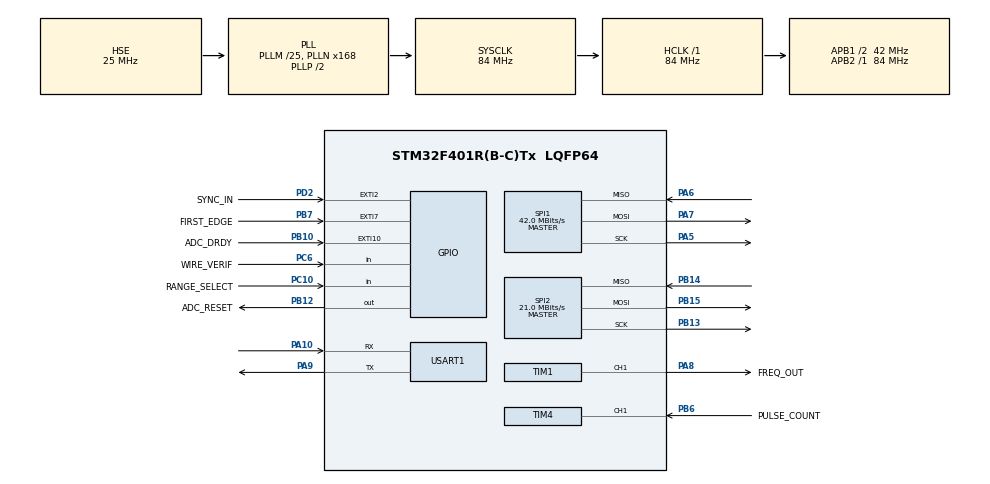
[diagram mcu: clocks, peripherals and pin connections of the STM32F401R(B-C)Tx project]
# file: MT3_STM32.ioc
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Mcu.Family=STM32F4
Mcu.Name=STM32F401R(B-C)Tx
Mcu.Package=LQFP64
NVIC.PriorityGroup=NVIC_PRIORITYGROUP_4
PA10.Mode=Asynchronous
PA10.Signal=USART1_RX
PA13.Mode=Serial_Wire
PA13.Signal=SYS_JTMS-SWDIO
PA14.Mode=Serial_Wire
PA14.Signal=SYS_JTCK-SWCLK
PA5.Mode=Full_Duplex_Master
PA5.Signal=SPI1_SCK
PA6.Mode=Full_Duplex_Master
PA6.Signal=SPI1_MISO
PA7.Mode=Full_Duplex_Master
PA7.Signal=SPI1_MOSI
PA8.GPIO_Label=FREQ_OUT
PA8.Signal=S_TIM1_CH1
PA9.Mode=Asynchronous
PA9.Signal=USART1_TX
PB10.GPIO_Label=ADC_DRDY
PB10.Signal=GPXTI10
PB12.GPIO_Label=ADC_RESET
PB12.Signal=GPIO_Output
PB13.Mode=Full_Duplex_Master
PB13.Signal=SPI2_SCK
PB14.Mode=Full_Duplex_Master
PB14.Signal=SPI2_MISO
PB15.Mode=Full_Duplex_Master
PB15.Signal=SPI2_MOSI
PB6.GPIO_Label=PULSE_COUNT
PB6.Signal=S_TIM4_CH1
PB7.GPIO_Label=FIRST_EDGE
PB7.Signal=GPXTI7
PC10.GPIO_Label=RANGE_SELECT
PC10.Signal=GPIO_Input
PC6.GPIO_Label=WIRE_VERIF
PC6.Signal=GPIO_Input
PD2.GPIO_Label=SYNC_IN
PD2.Signal=GPXTI2
PH0\ -\ OSC_IN.Mode=HSE-External-Oscillator
PH0\ -\ OSC_IN.Signal=RCC_OSC_IN
PH1\ -\ OSC_OUT.Mode=HSE-External-Oscillator
PH1\ -\ OSC_OUT.Signal=RCC_OSC_OUT
ProjectManager.HeapSize=0x200
ProjectManager.StackSize=0x400
ProjectManager.TargetToolchain=CMake
RCC.48MHZClocksFreq_Value=42000000
RCC.AHBFreq_Value=84000000
RCC.APB1CLKDivider=RCC_HCLK_DIV2
RCC.APB1Freq_Value=42000000
RCC.APB1TimFreq_Value=84000000
RCC.APB2Freq_Value=84000000
RCC.APB2TimFreq_Value=84000000
RCC.CortexFreq_Value=84000000
RCC.HCLKFreq_Value=84000000
RCC.HSE_VALUE=25000000
RCC.HSI_VALUE=16000000
RCC.LSE_VALUE=32768
RCC.PLLM=25
RCC.PLLN=168
RCC.PLLSourceVirtual=RCC_PLLSOURCE_HSE
RCC.SYSCLKFreq_VALUE=84000000
RCC.SYSCLKSource=RCC_SYSCLKSOURCE_PLLCLK
RCC.VCOOutputFreq_Value=168000000
SH.S_TIM1_CH1.0=TIM1_CH1,PWM Generation1 CH1
SH.S_TIM4_CH1.0=TIM4_CH1,Input_Capture1_from_TI1
SPI1.BaudRatePrescaler=SPI_BAUDRATEPRESCALER_2
SPI1.CalculateBaudRate=42.0 MBits/s
SPI1.Direction=SPI_DIRECTION_2LINES
SPI1.Mode=SPI_MODE_MASTER
SPI1.VirtualType=VM_MASTER
SPI2.BaudRatePrescaler=SPI_BAUDRATEPRESCALER_2
SPI2.CalculateBaudRate=21.0 MBits/s
SPI2.Direction=SPI_DIRECTION_2LINES
SPI2.Mode=SPI_MODE_MASTER
SPI2.VirtualType=VM_MASTER
TIM1.Channel-PWM\ Generation1\ CH1=TIM_CHANNEL_1
TIM4.Channel-Input_Capture1_from_TI1=TIM_CHANNEL_1
USART1.VirtualMode=VM_ASYNC
board=custom

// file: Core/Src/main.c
/* USER CODE BEGIN Header */
/**
  ******************************************************************************
  * @file           : main.c
  * @brief          : Main program body
  ******************************************************************************
  * @attention
  *
  * Copyright (c) 2026 STMicroelectronics.
  * All rights reserved.
  *
  * This software is licensed under terms that can be found in the LICENSE file
  * in the root directory of this software component.
  * If no LICENSE file comes with this software, it is provided AS-IS.
  *
  ******************************************************************************
  */
/* USER CODE END Header */
#include "main.h"
#include "spi.h"
#include "tim.h"
#include "usart.h"
#include "gpio.h"

/* USER CODE BEGIN Includes */
#include "mvp_telemetry.h"

/* USER CODE END Includes */

void SystemClock_Config(void);

int main(void)
{

  /* MCU Configuration--------------------------------------------------------*/

  /* Reset of all peripherals, Initializes the Flash interface and the Systick. */
  HAL_Init();

  /* Configure the system clock */
  SystemClock_Config();

  /* Initialize all configured peripherals */
  MX_GPIO_Init();
  MX_SPI1_Init();
  MX_SPI2_Init();
  MX_TIM1_Init();
  MX_TIM4_Init();
  MX_USART1_UART_Init();
  /* USER CODE BEGIN 2 */
  MvpTelemetry_Init();

  /* USER CODE END 2 */

  /* Infinite loop */
  while (1)
  {

    /* USER CODE BEGIN 3 */
    MvpTelemetry_Poll();
    __WFI();
  }
  /* USER CODE END 3 */
}

void SystemClock_Config(void)
{
  RCC_OscInitTypeDef RCC_OscInitStruct = {0};
  RCC_ClkInitTypeDef RCC_ClkInitStruct = {0};

  /** Configure the main internal regulator output voltage
  */
  __HAL_RCC_PWR_CLK_ENABLE();
  __HAL_PWR_VOLTAGESCALING_CONFIG(PWR_REGULATOR_VOLTAGE_SCALE2);

  /** Initializes the RCC Oscillators according to the specified parameters
  * in the RCC_OscInitTypeDef structure.
  */
  RCC_OscInitStruct.OscillatorType = RCC_OSCILLATORTYPE_HSE;
  RCC_OscInitStruct.HSEState = RCC_HSE_ON;
  RCC_OscInitStruct.PLL.PLLState = RCC_PLL_ON;
  RCC_OscInitStruct.PLL.PLLSource = RCC_PLLSOURCE_HSE;
  RCC_OscInitStruct.PLL.PLLM = 25;
  RCC_OscInitStruct.PLL.PLLN = 168;
  RCC_OscInitStruct.PLL.PLLP = RCC_PLLP_DIV2;
  RCC_OscInitStruct.PLL.PLLQ = 4;
  if (HAL_RCC_OscConfig(&RCC_OscInitStruct) != HAL_OK)
  {
    Error_Handler();
  }

  /** Initializes the CPU, AHB and APB buses clocks
  */
  RCC_ClkInitStruct.ClockType = RCC_CLOCKTYPE_HCLK|RCC_CLOCKTYPE_SYSCLK
                              |RCC_CLOCKTYPE_PCLK1|RCC_CLOCKTYPE_PCLK2;
  RCC_ClkInitStruct.SYSCLKSource = RCC_SYSCLKSOURCE_PLLCLK;
  RCC_ClkInitStruct.AHBCLKDivider = RCC_SYSCLK_DIV1;
  RCC_ClkInitStruct.APB1CLKDivider = RCC_HCLK_DIV2;
  RCC_ClkInitStruct.APB2CLKDivider = RCC_HCLK_DIV1;

  if (HAL_RCC_ClockConfig(&RCC_ClkInitStruct, FLASH_LATENCY_2) != HAL_OK)
  {
    Error_Handler();
  }
}

void Error_Handler(void)
{
  __disable_irq();
  while (1)
  {
  }
}
